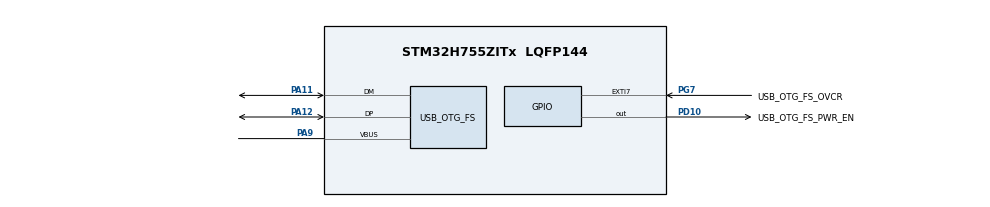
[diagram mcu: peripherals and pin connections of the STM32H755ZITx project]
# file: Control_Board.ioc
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CortexM4.IPs=FATFS_M4\:I,FREERTOS_M4\:I,IWDG2\:I,RCC,WWDG2\:I,DMA,BDMA,MDMA,NVIC2\:I,USART3,DEBUG,PDM2PCM_M4\:I,PWR,RESMGR_UTILITY,SYS_M4\:I,USB_DEVICE_M4\:I,USB_HOST_M4\:I,CORTEX_M4\:I,GPIO,OPENAMP_M4\:I,VREFBUF,NUCLEO-H755ZI-Q,TIM7\:I
CortexM7.IPs=FATFS_M7\:I,FREERTOS_M7\:I,IWDG1\:I,RCC\:I,WWDG1\:I,DMA\:I,BDMA\:I,MDMA\:I,NVIC1\:I,USART3\:I,USB_OTG_FS\:I,USB_OTG_FS1\:I,SYS\:I,CORTEX_M7\:I,DEBUG\:I,PDM2PCM_M7\:I,PWR\:I,RESMGR_UTILITY\:I,USB_DEVICE_M7\:I,USB_HOST_M7\:I,GPIO\:I,OPENAMP_M7\:I,VREFBUF\:I,NUCLEO-H755ZI-Q\:I,MEMORYMAP\:I,TIM6\:I
CortexM7.Pins=PD10,PG7
FREERTOS_M4.Tasks01=defaultTask,24,128,StartDefaultTask,Default,NULL,Dynamic,NULL,NULL
FREERTOS_M4.configENABLE_FPU=1
FREERTOS_M7.Tasks01=defaultTask,24,128,StartDefaultTask,Default,NULL,Dynamic,NULL,NULL
FREERTOS_M7.configENABLE_FPU=1
Mcu.Family=STM32H7
Mcu.Name=STM32H755ZITx
Mcu.Package=LQFP144
NUCLEO-H755ZI-Q.BUTTON=1
NUCLEO-H755ZI-Q.LD1=true
NUCLEO-H755ZI-Q.LD2=true
NUCLEO-H755ZI-Q.LD3=true
NUCLEO-H755ZI-Q.VCP=true
NVIC1.EXTI15_10_IRQn=true\:5\:0\:false\:false\:true\:true\:false\:true\:true
NVIC1.OTG_FS_WKUP_IRQn=true\:5\:0\:false\:false\:true\:true\:false\:true\:true
NVIC1.PriorityGroup=NVIC_PRIORITYGROUP_4
NVIC1.TIM6_DAC_IRQn=true\:15\:0\:false\:false\:true\:false\:false\:true\:true
NVIC1.TimeBase=TIM6_DAC_IRQn
NVIC1.TimeBaseIP=TIM6
NVIC2.PriorityGroup=NVIC_PRIORITYGROUP_4
NVIC2.TIM7_IRQn=true\:15\:0\:false\:false\:true\:false\:false\:true\:true
NVIC2.TimeBase=TIM7_IRQn
NVIC2.TimeBaseIP=TIM7
PA11.Mode=Device_Only
PA11.PinAttribute=CortexM7
PA11.Signal=USB_OTG_FS_DM
PA12.Mode=Device_Only
PA12.PinAttribute=CortexM7
PA12.Signal=USB_OTG_FS_DP
PA9.Mode=Activate_VBUS
PA9.PinAttribute=CortexM7
PA9.Signal=USB_OTG_FS_VBUS
PD10.GPIO_Label=USB_OTG_FS_PWR_EN
PD10.PinAttribute=CortexM7
PD10.Signal=GPIO_Output
PD8.Signal=USART3_TX
PD9.Signal=USART3_RX
PG7.GPIO_Label=USB_OTG_FS_OVCR
PG7.PinAttribute=CortexM7
PG7.Signal=GPXTI7
PH0-OSC_IN\ (PH0).Mode=HSE-External-Clock-Source
PH0-OSC_IN\ (PH0).PinAttribute=Free
PH0-OSC_IN\ (PH0).Signal=RCC_OSC_IN
ProjectManager.HeapSize=M4-0x400,M7-0x2000
ProjectManager.StackSize=M4-0x800,M7-0x4000
ProjectManager.TargetToolchain=CMake
RCC.ADCFreq_Value=38400000
RCC.APB1Freq_Value=90000000
RCC.APB2Freq_Value=90000000
RCC.APB3Freq_Value=90000000
RCC.APB4Freq_Value=90000000
RCC.CortexFreq_Value=360000000
RCC.D1PPRE=RCC_APB3_DIV2
RCC.D2PPRE1=RCC_APB1_DIV2
RCC.D2PPRE2=RCC_APB2_DIV2
RCC.D3PPRE=RCC_APB4_DIV2
RCC.DIVM1=2
RCC.DIVM2=5
RCC.DIVM3=2
RCC.DIVN1=180
RCC.DIVN2=48
RCC.DIVN3=72
RCC.DIVQ1=20
RCC.DIVQ3=6
RCC.HCLKFreq_Value=180000000
RCC.HPRE=RCC_HCLK_DIV2
RCC.HSE_VALUE=8000000
RCC.PLL2FRACN=0
RCC.PLL3FRACN=0
RCC.PLLFRACN=0
RCC.PLLSourceVirtual=RCC_PLLSOURCE_HSE
RCC.SYSCLKFreq_VALUE=360000000
RCC.SYSCLKSource=RCC_SYSCLKSOURCE_PLLCLK
RCC.SupplySource=PWR_DIRECT_SMPS_SUPPLY
RCC.USBCLockSelection=RCC_USBCLKSOURCE_PLL3
RCC.USBFreq_Value=48000000
USB_OTG_FS.VirtualMode=Device_Only
USB_OTG_FS.low_power_enable=ENABLE
VP_FREERTOS_M4_VS_CMSIS_V2.Mode=CMSIS_V2
VP_FREERTOS_M7_VS_CMSIS_V2.Mode=CMSIS_V2
VP_MEMORYMAP_VS_MEMORYMAP.Mode=CurAppReg
VP_NUCLEO-H755ZI-Q_VS_BSP_COMMON.Mode=COMMON
VP_SYS_M4_VS_tim7.Mode=TIM7
VP_SYS_VS_tim6.Mode=TIM6
board=NUCLEO-H755ZI-Q

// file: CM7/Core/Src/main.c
/* USER CODE BEGIN Header */
/**
 ******************************************************************************
 * @file           : main.c
 * @brief          : Main program body
 ******************************************************************************
 * @attention
 *
 * Copyright (c) 2026 STMicroelectronics.
 * All rights reserved.
 *
 * This software is licensed under terms that can be found in the LICENSE file
 * in the root directory of this software component.
 * If no LICENSE file comes with this software, it is provided AS-IS.
 *
 ******************************************************************************
 */
/* USER CODE END Header */
#include "main.h"
#include "FreeRTOS.h"
#include "cmsis_os2.h"

/* USER CODE BEGIN Includes */
#include "emc_h755_gpio.h"
/* USER CODE END Includes */

/* USER CODE BEGIN PD */

/* DUAL_CORE_BOOT_SYNC_SEQUENCE: Define for dual core boot synchronization    */
/*                             demonstration code based on hardware semaphore */
/* This define is present in both CM7/CM4 projects                            */
/* To comment when developping/debugging on a single core                     */
#define DUAL_CORE_BOOT_SYNC_SEQUENCE

#if defined(DUAL_CORE_BOOT_SYNC_SEQUENCE)
#ifndef HSEM_ID_0
#define HSEM_ID_0 (0U) /* HW semaphore 0*/
#endif
#endif /* DUAL_CORE_BOOT_SYNC_SEQUENCE */

/* USER CODE END PD */

COM_InitTypeDef BspCOMInit;

PCD_HandleTypeDef hpcd_USB_OTG_FS;

/* Definitions for defaultTask */
osThreadId_t defaultTaskHandle;
const osThreadAttr_t defaultTask_attributes = {
    .name = "defaultTask",
    .stack_size = 128 * 4,
    .priority = (osPriority_t)osPriorityNormal,
};

void SystemClock_Config(void);
static void MX_GPIO_Init(void);
static void MX_USB_OTG_FS_PCD_Init(void);
void StartDefaultTask(void *argument);

int main(void) {

/* USER CODE BEGIN Boot_Mode_Sequence_0 */
#if defined(DUAL_CORE_BOOT_SYNC_SEQUENCE)
  int32_t timeout;
#endif /* DUAL_CORE_BOOT_SYNC_SEQUENCE */
/* USER CODE END Boot_Mode_Sequence_0 */

/* USER CODE BEGIN Boot_Mode_Sequence_1 */
#if defined(DUAL_CORE_BOOT_SYNC_SEQUENCE)
  /* Wait until CPU2 boots and enters in stop mode or timeout*/
  timeout = 0xFFFF;
  while ((__HAL_RCC_GET_FLAG(RCC_FLAG_D2CKRDY) != RESET) && (timeout-- > 0))
    ;
  if (timeout < 0) {
    Error_Handler();
  }
#endif /* DUAL_CORE_BOOT_SYNC_SEQUENCE */
       /* USER CODE END Boot_Mode_Sequence_1 */
  /* MCU Configuration--------------------------------------------------------*/

  /* Reset of all peripherals, Initializes the Flash interface and the Systick.
   */
  HAL_Init();

  /* Configure the system clock */
  SystemClock_Config();
/* USER CODE BEGIN Boot_Mode_Sequence_2 */
#if defined(DUAL_CORE_BOOT_SYNC_SEQUENCE)
  /* When system initialization is finished, Cortex-M7 will release Cortex-M4 by
  means of HSEM notification */
  /*HW semaphore Clock enable*/
  __HAL_RCC_HSEM_CLK_ENABLE();
  /*Take HSEM */
  HAL_HSEM_FastTake(HSEM_ID_0);
  /*Release HSEM in order to notify the CPU2(CM4)*/
  HAL_HSEM_Release(HSEM_ID_0, 0);
  /* wait until CPU2 wakes up from stop mode */
  timeout = 0xFFFF;
  while ((__HAL_RCC_GET_FLAG(RCC_FLAG_D2CKRDY) == RESET) && (timeout-- > 0))
    ;
  if (timeout < 0) {
    Error_Handler();
  }
#endif /* DUAL_CORE_BOOT_SYNC_SEQUENCE */
       /* USER CODE END Boot_Mode_Sequence_2 */

  /* Initialize all configured peripherals */
  MX_GPIO_Init();
  MX_USB_OTG_FS_PCD_Init();

  /* Init scheduler */
  osKernelInitialize();

  /* Create the thread(s) */
  /* creation of defaultTask */
  defaultTaskHandle =
      osThreadNew(StartDefaultTask, NULL, &defaultTask_attributes);

  /* Initialize leds */
  BSP_LED_Init(LED_GREEN);
  //BSP_LED_Init(LED_YELLOW);
  BSP_LED_Init(LED_RED);

  /* Initialize USER push-button, will be used to trigger an interrupt each time
   * it's pressed.*/
  BSP_PB_Init(BUTTON_USER, BUTTON_MODE_EXTI);

  /* Initialize COM1 port (115200, 8 bits (7-bit data + 1 stop bit), no parity
   */
  BspCOMInit.BaudRate = 115200;
  BspCOMInit.WordLength = COM_WORDLENGTH_8B;
  BspCOMInit.StopBits = COM_STOPBITS_1;
  BspCOMInit.Parity = COM_PARITY_NONE;
  BspCOMInit.HwFlowCtl = COM_HWCONTROL_NONE;
  if (BSP_COM_Init(COM1, &BspCOMInit) != BSP_ERROR_NONE) {
    Error_Handler();
  }

  /* Start scheduler */
  osKernelStart();

  /* We should never get here as control is now taken by the scheduler */

  /* Infinite loop */
  while (1) {

  }
}

void SystemClock_Config(void) {
  RCC_OscInitTypeDef RCC_OscInitStruct = {0};
  RCC_ClkInitTypeDef RCC_ClkInitStruct = {0};

  /** Supply configuration update enable
   */
  HAL_PWREx_ConfigSupply(PWR_DIRECT_SMPS_SUPPLY);

  /** Configure the main internal regulator output voltage
   */
  __HAL_PWR_VOLTAGESCALING_CONFIG(PWR_REGULATOR_VOLTAGE_SCALE1);

  while (!__HAL_PWR_GET_FLAG(PWR_FLAG_VOSRDY)) {
  }

  /** Initializes the RCC Oscillators according to the specified parameters
   * in the RCC_OscInitTypeDef structure.
   */
  RCC_OscInitStruct.OscillatorType = RCC_OSCILLATORTYPE_HSE;
  RCC_OscInitStruct.HSEState = RCC_HSE_BYPASS;
  RCC_OscInitStruct.PLL.PLLState = RCC_PLL_ON;
  RCC_OscInitStruct.PLL.PLLSource = RCC_PLLSOURCE_HSE;
  RCC_OscInitStruct.PLL.PLLM = 2;
  RCC_OscInitStruct.PLL.PLLN = 180;
  RCC_OscInitStruct.PLL.PLLP = 2;
  RCC_OscInitStruct.PLL.PLLQ = 20;
  RCC_OscInitStruct.PLL.PLLR = 2;
  RCC_OscInitStruct.PLL.PLLRGE = RCC_PLL1VCIRANGE_2;
  RCC_OscInitStruct.PLL.PLLVCOSEL = RCC_PLL1VCOWIDE;
  RCC_OscInitStruct.PLL.PLLFRACN = 0;
  if (HAL_RCC_OscConfig(&RCC_OscInitStruct) != HAL_OK) {
    Error_Handler();
  }

  /** Initializes the CPU, AHB and APB buses clocks
   */
  RCC_ClkInitStruct.ClockType = RCC_CLOCKTYPE_HCLK | RCC_CLOCKTYPE_SYSCLK |
                                RCC_CLOCKTYPE_PCLK1 | RCC_CLOCKTYPE_PCLK2 |
                                RCC_CLOCKTYPE_D3PCLK1 | RCC_CLOCKTYPE_D1PCLK1;
  RCC_ClkInitStruct.SYSCLKSource = RCC_SYSCLKSOURCE_PLLCLK;
  RCC_ClkInitStruct.SYSCLKDivider = RCC_SYSCLK_DIV1;
  RCC_ClkInitStruct.AHBCLKDivider = RCC_HCLK_DIV2;
  RCC_ClkInitStruct.APB3CLKDivider = RCC_APB3_DIV2;
  RCC_ClkInitStruct.APB1CLKDivider = RCC_APB1_DIV2;
  RCC_ClkInitStruct.APB2CLKDivider = RCC_APB2_DIV2;
  RCC_ClkInitStruct.APB4CLKDivider = RCC_APB4_DIV2;

  if (HAL_RCC_ClockConfig(&RCC_ClkInitStruct, FLASH_LATENCY_2) != HAL_OK) {
    Error_Handler();
  }
}

static void MX_USB_OTG_FS_PCD_Init(void) {

  hpcd_USB_OTG_FS.Instance = USB_OTG_FS;
  hpcd_USB_OTG_FS.Init.dev_endpoints = 9;
  hpcd_USB_OTG_FS.Init.speed = PCD_SPEED_FULL;
  hpcd_USB_OTG_FS.Init.dma_enable = DISABLE;
  hpcd_USB_OTG_FS.Init.phy_itface = PCD_PHY_EMBEDDED;
  hpcd_USB_OTG_FS.Init.Sof_enable = DISABLE;
  hpcd_USB_OTG_FS.Init.low_power_enable = ENABLE;
  hpcd_USB_OTG_FS.Init.lpm_enable = DISABLE;
  hpcd_USB_OTG_FS.Init.battery_charging_enable = ENABLE;
  hpcd_USB_OTG_FS.Init.vbus_sensing_enable = ENABLE;
  hpcd_USB_OTG_FS.Init.use_dedicated_ep1 = DISABLE;
  if (HAL_PCD_Init(&hpcd_USB_OTG_FS) != HAL_OK) {
    Error_Handler();
  }
}

static void MX_GPIO_Init(void) {
  GPIO_InitTypeDef GPIO_InitStruct = {0};

  /* GPIO Ports Clock Enable */
  __HAL_RCC_GPIOD_CLK_ENABLE();
  __HAL_RCC_GPIOG_CLK_ENABLE();
  __HAL_RCC_GPIOA_CLK_ENABLE();

  /*Configure GPIO pin Output Level */
  HAL_GPIO_WritePin(USB_OTG_FS_PWR_EN_GPIO_Port, USB_OTG_FS_PWR_EN_Pin,
                    GPIO_PIN_RESET);

  /*Configure GPIO pin : USB_OTG_FS_PWR_EN_Pin */
  GPIO_InitStruct.Pin = USB_OTG_FS_PWR_EN_Pin;
  GPIO_InitStruct.Mode = GPIO_MODE_OUTPUT_PP;
  GPIO_InitStruct.Pull = GPIO_NOPULL;
  GPIO_InitStruct.Speed = GPIO_SPEED_FREQ_LOW;
  HAL_GPIO_Init(USB_OTG_FS_PWR_EN_GPIO_Port, &GPIO_InitStruct);

  /*Configure GPIO pin : USB_OTG_FS_OVCR_Pin */
  GPIO_InitStruct.Pin = USB_OTG_FS_OVCR_Pin;
  GPIO_InitStruct.Mode = GPIO_MODE_IT_RISING;
  GPIO_InitStruct.Pull = GPIO_NOPULL;
  HAL_GPIO_Init(USB_OTG_FS_OVCR_GPIO_Port, &GPIO_InitStruct);

}

void StartDefaultTask(void *argument) {
  /* USER CODE BEGIN 5 */
  __HAL_RCC_GPIOE_CLK_ENABLE();
  gpioledpe1();

  // GPIO_InitTypeDef GPIO_InitStruct = {0};
  // GPIO_InitStruct.Pin = GPIO_PIN_1;           // PE1 (Sarı LED)
  // GPIO_InitStruct.Mode = GPIO_MODE_OUTPUT_PP; // Push-Pull Çıkış
  // GPIO_InitStruct.Pull = GPIO_NOPULL;
  // GPIO_InitStruct.Speed = GPIO_SPEED_FREQ_LOW;
  // HAL_GPIO_Init(GPIOE, &GPIO_InitStruct);
  /* Infinite loop */
  for (;;) {
    osDelay(500);
    // HAL_GPIO_WritePin(GPIOE, GPIO_PIN_1, GPIO_PIN_SET);
    EMC_GPIOE->BSRRSET = 1U << 1;
    osDelay(500);
    //  HAL_GPIO_WritePin(GPIOE, GPIO_PIN_1, GPIO_PIN_RESET);
    EMC_GPIOE->BSRRRESET = 1U << 1;
  }
  /* USER CODE END 5 */
}

void HAL_TIM_PeriodElapsedCallback(TIM_HandleTypeDef *htim) {
  if (htim->Instance == TIM6) {
    HAL_IncTick();
  }
}

void Error_Handler(void) {
  __disable_irq();
  while (1) {
  }
}
#ifdef USE_FULL_ASSERT
/**
 * @brief  Reports the name of the source file and the source line number
 *         where the assert_param error has occurred.
 * @param  file: pointer to the source file name
 * @param  line: assert_param error line source number
 * @retval None
 */
void assert_failed(uint8_t *file, uint32_t line) {
  /* USER CODE BEGIN 6 */
  /* User can add his own implementation to report the file name and line
     number, ex: printf("Wrong parameters value: file %s on line %d\r\n", file,
     line) */
  /* USER CODE END 6 */
}
#endif /* USE_FULL_ASSERT */
